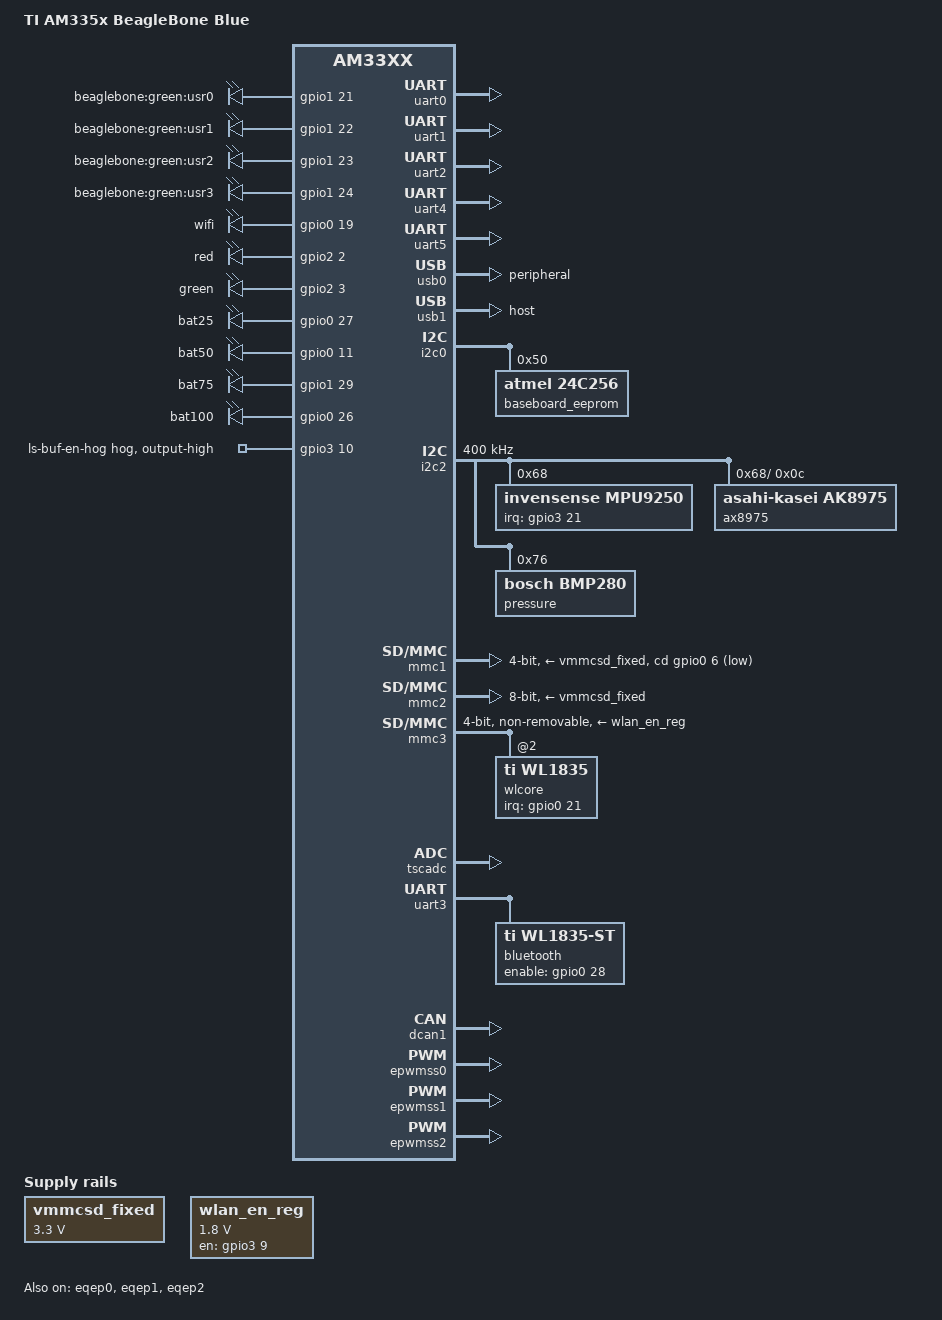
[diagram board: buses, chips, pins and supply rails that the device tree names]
/dts-v1/;
#include "am33xx.dtsi"
#include "am335x-osd335x-common.dtsi"
#include <dt-bindings/interrupt-controller/irq.h>
/ {
	model = "TI AM335x BeagleBone Blue";
	compatible = "ti,am335x-bone-blue", "ti,am33xx";
	chosen {
		stdout-path = &uart0;
	};
	leds {
		pinctrl-names = "default";
		pinctrl-0 = <&user_leds_s0>;
		compatible = "gpio-leds";
		usr_0_led {
			label = "beaglebone:green:usr0";
			gpios = <&gpio1 21 GPIO_ACTIVE_HIGH>;
			linux,default-trigger = "heartbeat";
			default-state = "off";
		};
		usr_1_led {
			label = "beaglebone:green:usr1";
			gpios = <&gpio1 22 GPIO_ACTIVE_HIGH>;
			linux,default-trigger = "mmc0";
			default-state = "off";
		};
		usr_2_led {
			label = "beaglebone:green:usr2";
			gpios = <&gpio1 23 GPIO_ACTIVE_HIGH>;
			linux,default-trigger = "cpu0";
			default-state = "off";
		};
		usr_3_led {
			label = "beaglebone:green:usr3";
			gpios = <&gpio1 24 GPIO_ACTIVE_HIGH>;
			linux,default-trigger = "mmc1";
			default-state = "off";
		};
		wifi_led {
			label = "wifi";
			gpios = <&gpio0 19 GPIO_ACTIVE_HIGH>;
			default-state = "off";
			linux,default-trigger = "phy0assoc";
		};
		red_led {
			label = "red";
			gpios = <&gpio2 2 GPIO_ACTIVE_HIGH>;
			default-state = "off";
		};
		green_led {
			label = "green";
			gpios = <&gpio2 3 GPIO_ACTIVE_HIGH>;
			default-state = "off";
		};
		batt_1_led {
			label = "bat25";
			gpios = <&gpio0 27 GPIO_ACTIVE_HIGH>;
			default-state = "off";
		};
		batt_2_led {
			label = "bat50";
			gpios = <&gpio0 11 GPIO_ACTIVE_HIGH>;
			default-state = "off";
		};
		batt_3_led {
			label = "bat75";
			gpios = <&gpio1 29 GPIO_ACTIVE_HIGH>;
			default-state = "off";
		};
		batt_4_led {
			label = "bat100";
			gpios = <&gpio0 26 GPIO_ACTIVE_HIGH>;
			default-state = "off";
		};
	};
	vmmcsd_fixed: fixedregulator0 {
		compatible = "regulator-fixed";
		regulator-name = "vmmcsd_fixed";
		regulator-min-microvolt = <3300000>;
		regulator-max-microvolt = <3300000>;
	};
	wlan_en_reg: fixedregulator@2 {
		compatible = "regulator-fixed";
		regulator-name = "wlan-en-regulator";
		regulator-min-microvolt = <1800000>;
		regulator-max-microvolt = <1800000>;
		startup-delay-us = <70000>;
		gpio = <&gpio3 9 0>;
		enable-active-high;
	};
};
&am33xx_pinmux {
	user_leds_s0: user-leds-s0-pins {
		pinctrl-single,pins = <
			AM33XX_PADCONF(AM335X_PIN_GPMC_A5, PIN_OUTPUT, MUX_MODE7)  
			AM33XX_PADCONF(AM335X_PIN_GPMC_A6, PIN_OUTPUT, MUX_MODE7)  
			AM33XX_PADCONF(AM335X_PIN_GPMC_A7, PIN_OUTPUT, MUX_MODE7)  
			AM33XX_PADCONF(AM335X_PIN_GPMC_A8, PIN_OUTPUT, MUX_MODE7)  
			AM33XX_PADCONF(AM335X_PIN_XDMA_EVENT_INTR0, PIN_OUTPUT, MUX_MODE7)  
			AM33XX_PADCONF(AM335X_PIN_GPMC_ADVN_ALE, PIN_OUTPUT, MUX_MODE7)  
			AM33XX_PADCONF(AM335X_PIN_GPMC_OEN_REN, PIN_OUTPUT, MUX_MODE7)  
			AM33XX_PADCONF(AM335X_PIN_GPMC_AD11, PIN_OUTPUT, MUX_MODE7)  
			AM33XX_PADCONF(AM335X_PIN_LCD_DATA15, PIN_OUTPUT, MUX_MODE7)  
			AM33XX_PADCONF(AM335X_PIN_GPMC_CSN0, PIN_OUTPUT, MUX_MODE7)  
			AM33XX_PADCONF(AM335X_PIN_GPMC_AD10, PIN_OUTPUT, MUX_MODE7)  
		>;
	};
	i2c2_pins: i2c2-pins {
		pinctrl-single,pins = <
			AM33XX_PADCONF(AM335X_PIN_UART1_CTSN, PIN_INPUT_PULLUP, MUX_MODE3)	 
			AM33XX_PADCONF(AM335X_PIN_UART1_RTSN, PIN_INPUT_PULLUP, MUX_MODE3)	 
		>;
	};
	uart0_pins: uart0-pins {
		pinctrl-single,pins = <
			AM33XX_PADCONF(AM335X_PIN_UART0_RXD, PIN_INPUT_PULLUP, MUX_MODE0)
			AM33XX_PADCONF(AM335X_PIN_UART0_TXD, PIN_OUTPUT_PULLDOWN, MUX_MODE0)
		>;
	};
	uart1_pins: uart1-pins {
		pinctrl-single,pins = <
			AM33XX_PADCONF(AM335X_PIN_UART1_RXD, PIN_INPUT_PULLUP, MUX_MODE0)
			AM33XX_PADCONF(AM335X_PIN_UART1_TXD, PIN_OUTPUT_PULLDOWN, MUX_MODE0)
		>;
	};
	uart2_pins: uart2-pins {
		pinctrl-single,pins = <
			AM33XX_PADCONF(AM335X_PIN_SPI0_SCLK, PIN_INPUT_PULLUP, MUX_MODE1)	 
			AM33XX_PADCONF(AM335X_PIN_SPI0_D0, PIN_OUTPUT_PULLDOWN, MUX_MODE1)	 
		>;
	};
	uart4_pins: uart4-pins {
		pinctrl-single,pins = <
			AM33XX_PADCONF(AM335X_PIN_GPMC_WAIT0, PIN_INPUT_PULLUP, MUX_MODE6)	 
		>;
	};
	uart5_pins: uart5-pins {
		pinctrl-single,pins = <
			AM33XX_PADCONF(AM335X_PIN_LCD_DATA9, PIN_INPUT_PULLUP, MUX_MODE4)	 
			AM33XX_PADCONF(AM335X_PIN_LCD_DATA8, PIN_OUTPUT_PULLDOWN, MUX_MODE4)	 
		>;
	};
	mmc1_pins: mmc1-pins {
		pinctrl-single,pins = <
			AM33XX_PADCONF(AM335X_PIN_SPI0_CS1, PIN_INPUT, MUX_MODE7)		 
		>;
	};
	mmc2_pins: mmc2-pins {
		pinctrl-single,pins = <
			AM33XX_PADCONF(AM335X_PIN_GPMC_CSN1, PIN_INPUT_PULLUP, MUX_MODE2)	 
			AM33XX_PADCONF(AM335X_PIN_GPMC_CSN2, PIN_INPUT_PULLUP, MUX_MODE2)	 
			AM33XX_PADCONF(AM335X_PIN_GPMC_AD0, PIN_INPUT_PULLUP, MUX_MODE1)	 
			AM33XX_PADCONF(AM335X_PIN_GPMC_AD1, PIN_INPUT_PULLUP, MUX_MODE1)	 
			AM33XX_PADCONF(AM335X_PIN_GPMC_AD2, PIN_INPUT_PULLUP, MUX_MODE1)	 
			AM33XX_PADCONF(AM335X_PIN_GPMC_AD3, PIN_INPUT_PULLUP, MUX_MODE1)	 
			AM33XX_PADCONF(AM335X_PIN_GPMC_AD4, PIN_INPUT_PULLUP, MUX_MODE1)	 
			AM33XX_PADCONF(AM335X_PIN_GPMC_AD5, PIN_INPUT_PULLUP, MUX_MODE1)	 
			AM33XX_PADCONF(AM335X_PIN_GPMC_AD6, PIN_INPUT_PULLUP, MUX_MODE1)	 
			AM33XX_PADCONF(AM335X_PIN_GPMC_AD7, PIN_INPUT_PULLUP, MUX_MODE1)	 
		>;
	};
	mmc3_pins: mmc3-pins {
		pinctrl-single,pins = <
			AM33XX_PADCONF(AM335X_PIN_MII1_RXD1, PIN_INPUT_PULLUP, MUX_MODE6)	 
			AM33XX_PADCONF(AM335X_PIN_MII1_TX_EN, PIN_INPUT_PULLUP, MUX_MODE6)	 
			AM33XX_PADCONF(AM335X_PIN_MII1_RX_DV, PIN_INPUT_PULLUP, MUX_MODE5)	 
			AM33XX_PADCONF(AM335X_PIN_MII1_TXD3, PIN_INPUT_PULLUP, MUX_MODE5)	 
			AM33XX_PADCONF(AM335X_PIN_MII1_TXD2, PIN_INPUT_PULLUP, MUX_MODE5)	 
			AM33XX_PADCONF(AM335X_PIN_MII1_COL, PIN_INPUT_PULLUP, MUX_MODE5)	 
		>;
	};
	bt_pins: bt-pins {
		pinctrl-single,pins = <
			AM33XX_PADCONF(AM335X_PIN_MII1_TXD0, PIN_OUTPUT_PULLUP, MUX_MODE7)	 
		>;
	};
	uart3_pins: uart3-pins {
		pinctrl-single,pins = <
			AM33XX_PADCONF(AM335X_PIN_MII1_RXD3, PIN_INPUT_PULLUP, MUX_MODE1)	 
			AM33XX_PADCONF(AM335X_PIN_MII1_RXD2, PIN_OUTPUT_PULLDOWN, MUX_MODE1)	 
			AM33XX_PADCONF(AM335X_PIN_MDIO, PIN_INPUT, MUX_MODE3)		 
			AM33XX_PADCONF(AM335X_PIN_MDC, PIN_OUTPUT_PULLDOWN, MUX_MODE3)	 
		>;
	};
	wl18xx_pins: wl18xx-pins {
		pinctrl-single,pins = <
			AM33XX_PADCONF(AM335X_PIN_MII1_TX_CLK, PIN_OUTPUT_PULLDOWN, MUX_MODE7)	 
			AM33XX_PADCONF(AM335X_PIN_MII1_TXD1, PIN_INPUT_PULLDOWN, MUX_MODE7)	 
			AM33XX_PADCONF(AM335X_PIN_MII1_RX_CLK, PIN_OUTPUT_PULLUP, MUX_MODE7)	 
		>;
	};
	dcan1_pins: dcan1-pins {
		pinctrl-single,pins = <
			AM33XX_PADCONF(AM335X_PIN_UART0_RTSN, PIN_INPUT, MUX_MODE2)		 
			AM33XX_PADCONF(AM335X_PIN_UART0_CTSN, PIN_OUTPUT, MUX_MODE2)		 
			AM33XX_PADCONF(AM335X_PIN_MII1_RXD0, PIN_OUTPUT, MUX_MODE7)		 
		>;
	};
	eqep0_pins: eqep0-pins {
		pinctrl-single,pins = <
			AM33XX_PADCONF(AM335X_PIN_MCASP0_AXR0, PIN_INPUT, MUX_MODE1)		 
			AM33XX_PADCONF(AM335X_PIN_MCASP0_FSR, PIN_INPUT, MUX_MODE1)		 
		>;
	};
	eqep1_pins: eqep1-pins {
		pinctrl-single,pins = <
			AM33XX_PADCONF(AM335X_PIN_LCD_DATA12, PIN_INPUT, MUX_MODE2)		 
			AM33XX_PADCONF(AM335X_PIN_LCD_DATA13, PIN_INPUT, MUX_MODE2)		 
		>;
	};
	eqep2_pins: eqep2-pins {
		pinctrl-single,pins = <
			AM33XX_PADCONF(AM335X_PIN_GPMC_AD12, PIN_INPUT, MUX_MODE4)		 
			AM33XX_PADCONF(AM335X_PIN_GPMC_AD13, PIN_INPUT, MUX_MODE4)		 
		>;
	};
};
&uart0 {
	pinctrl-names = "default";
	pinctrl-0 = <&uart0_pins>;
	status = "okay";
};
&uart1 {
	pinctrl-names = "default";
	pinctrl-0 = <&uart1_pins>;
	status = "okay";
};
&uart2 {
	pinctrl-names = "default";
	pinctrl-0 = <&uart2_pins>;
	status = "okay";
};
&uart4 {
	pinctrl-names = "default";
	pinctrl-0 = <&uart4_pins>;
	status = "okay";
};
&uart5 {
	pinctrl-names = "default";
	pinctrl-0 = <&uart5_pins>;
	status = "okay";
};
&usb0 {
	dr_mode = "peripheral";
	interrupts-extended = <&intc 18 &tps 0>;
	interrupt-names = "mc", "vbus";
};
&usb1 {
	dr_mode = "host";
};
&i2c0 {
	baseboard_eeprom: baseboard_eeprom@50 {
		compatible = "atmel,24c256";
		reg = <0x50>;
		#address-cells = <1>;
		#size-cells = <1>;
		baseboard_data: baseboard_data@0 {
			reg = <0 0x100>;
		};
	};
};
&i2c2 {
	pinctrl-names = "default";
	pinctrl-0 = <&i2c2_pins>;
	status = "okay";
	clock-frequency = <400000>;
	mpu9250@68 {
		compatible = "invensense,mpu9250";
		reg = <0x68>;
		interrupt-parent = <&gpio3>;
		interrupts = <21 IRQ_TYPE_EDGE_RISING>;
		i2c-gate {
			#address-cells = <1>;
			#size-cells = <0>;
			ax8975@c {
				compatible = "asahi-kasei,ak8975";
				reg = <0x0c>;
			};
		};
	};
	pressure@76 {
		compatible = "bosch,bmp280";
		reg = <0x76>;
	};
};
/include/ "../../tps65217.dtsi"
&tps {
	/delete-property/ ti,pmic-shutdown-controller;
	charger {
		interrupts = <0>, <1>;
		interrupt-names = "USB", "AC";
		status = "okay";
	};
};
&mmc1 {
	status = "okay";
	vmmc-supply = <&vmmcsd_fixed>;
	bus-width = <4>;
	pinctrl-names = "default";
	pinctrl-0 = <&mmc1_pins>;
	cd-gpios = <&gpio0 6 GPIO_ACTIVE_LOW>;
};
&mmc2 {
	status = "okay";
	vmmc-supply = <&vmmcsd_fixed>;
	bus-width = <8>;
	pinctrl-names = "default";
	pinctrl-0 = <&mmc2_pins>;
};
&mmc3 {
	dmas = <&edma_xbar 12 0 1
		&edma_xbar 13 0 2>;
	dma-names = "tx", "rx";
	status = "okay";
	vmmc-supply = <&wlan_en_reg>;
	bus-width = <4>;
	non-removable;
	cap-power-off-card;
	keep-power-in-suspend;
	pinctrl-names = "default";
	pinctrl-0 = <&mmc3_pins &wl18xx_pins>;
	#address-cells = <1>;
	#size-cells = <0>;
	wlcore: wlcore@2 {
		compatible = "ti,wl1835";
		reg = <2>;
		interrupt-parent = <&gpio0>;
		interrupts = <21 IRQ_TYPE_EDGE_RISING>;
	};
};
&tscadc {
	status = "okay";
	adc {
		ti,adc-channels = <0 1 2 3 4 5 6 7>;
	};
};
&uart3 {
	pinctrl-names = "default";
	pinctrl-0 = <&uart3_pins &bt_pins>;
	status = "okay";
	bluetooth {
		compatible = "ti,wl1835-st";
		enable-gpios = <&gpio0 28 GPIO_ACTIVE_HIGH>;
	};
};
&rtc {
	system-power-controller;
	clocks = <&clk_32768_ck>, <&clk_24mhz_clkctrl AM3_CLK_24MHZ_CLKDIV32K_CLKCTRL 0>;
	clock-names = "ext-clk", "int-clk";
};
&dcan1 {
	pinctrl-names = "default";
	pinctrl-0 = <&dcan1_pins>;
	status = "okay";
};
&gpio0 {
	gpio-line-names =
		"UART3_CTS",  
		"UART3_RTS",  
		"UART2_RX",  
		"UART2_TX",  
		"I2C1_SDA",  
		"I2C1_SCL",  
		"MMC0_CD",  
		"SPI1_SS2",  
		"EQEP_1A",  
		"EQEP_1B",  
		"MDIR_2B",  
		"BATT_LED_2",  
		"I2C2_SDA",  
		"I2C2_SCL",  
		"UART1_RX",  
		"UART1_TX",  
		"MMC2_DAT1",  
		"MMC2_DAT2",  
		"NC",  
		"WIFI_LED",  
		"MOT_STBY",  
		"WLAN_IRQ",  
		"PWM_2A",  
		"PWM_2B",  
		"",
		"",
		"BATT_LED_4",  
		"BATT_LED_1",  
		"BT_EN",  
		"SPI1_SS1",  
		"UART4_RX",  
		"MDIR_1B";  
};
&gpio1 {
	gpio-line-names =
		"MMC1_DAT0",  
		"MMC1_DAT1",  
		"MMC1_DAT2",  
		"MMC1_DAT3",  
		"MMC1_DAT4",  
		"MMC1_DAT5",  
		"MMC1_DAT6",  
		"MMC1_DAT7",  
		"DCAN1_TX",  
		"DCAN1_RX",  
		"UART0_RX",  
		"UART0_TX",  
		"EQEP_2A",  
		"EQEP_2B",  
		"PRU_E_A",  
		"PRU_E_B",  
		"MDIR_2A",  
		"GPIO1_17",  
		"PWM_1A",  
		"PWM_1B",  
		"EMMC_RST",  
		"USR_LED_0",  
		"USR_LED_1",  
		"USR_LED_2",  
		"USR_LED_3",  
		"GPIO1_25",  
		"MCASP0_AXR0",  
		"MCASP0_AXR1",  
		"MCASP0_ACLKR",  
		"BATT_LED_3",  
		"MMC1_CLK",  
		"MMC1_CMD";  
};
&gpio2 {
	gpio-line-names =
		"MDIR_1A",  
		"MCASP0_FSR",  
		"LED_RED",  
		"LED_GREEN",  
		"MODE_BTN",  
		"PAUSE_BTN",  
		"MDIR_4A",  
		"MDIR_4B",  
		"MDIR_3B",  
		"MDIR_3A",  
		"SVO7",  
		"SVO8",  
		"SVO5",  
		"SVO6",  
		"UART5_TX",  
		"UART5_RX",  
		"SERVO_EN",  
		"NC",  
		"UART3_RX",  
		"UART3_TX",  
		"MMC2_CLK",  
		"DCAN1_SILENT",  
		"SVO1",  
		"SVO3",  
		"SVO2",  
		"SVO4",  
		"MMC0_DAT3",  
		"MMC0_DAT2",  
		"MMC0_DAT1",  
		"MMC0_DAT0",  
		"MMC0_CLK",  
		"MMC0_CMD";  
};
&gpio3 {
	gpio-line-names =
		"MMC2_DAT3",  
		"GPIO3_1",  
		"GPIO3_2",  
		"MMC2_CMD",  
		"MMC2_DAT0",  
		"I2C0_SDA",  
		"I2C0_SCL",  
		"EMU1",  
		"EMU0",  
		"WL_EN",  
		"WL_BT_OE",  
		"",
		"",
		"NC",  
		"SPI1_SCK",  
		"SPI1_MISO",  
		"SPI1_MOSI",  
		"GPIO3_17",  
		"EQEP_0A",  
		"EQEP_0B",  
		"GPIO3_20",  
		"IMU_INT",  
		"",
		"",
		"",
		"",
		"",
		"",
		"",
		"",
		"",
		"";
	ls-buf-en-hog {
		gpio-hog;
		gpios = <10 GPIO_ACTIVE_HIGH>;
		output-high;
	};
};
&epwmss0 {
	status = "okay";
};
&eqep0 {
	pinctrl-names = "default";
	pinctrl-0 = <&eqep0_pins>;
	status = "okay";
};
&epwmss1 {
	status = "okay";
};
&eqep1 {
	pinctrl-names = "default";
	pinctrl-0 = <&eqep1_pins>;
	status = "okay";
};
&epwmss2 {
	status = "okay";
};
&eqep2 {
	pinctrl-names = "default";
	pinctrl-0 = <&eqep2_pins>;
	status = "okay";
};
